# PY32F021xx register map
Vendor: Puya; Series: PY32C; File version: 1.0.0
Arm 32-bit Cortex-M0+ Microcontroller based device, CPU clock up to 48 MHz.
CPU: CM0+ r0p1, little endian, no MPU, no FPU, 4 interrupt priority bits
Registers are 32-bit, read-write, reset 0x0 unless marked. A register's access mark holds for its fields unless they carry their own. Offsets are from the block's base; lines under a group give offsets from that group; [hi:lo] are bit positions; {n}, {i} and the like mark numbered series; 'fields as' and 'values as' point back to an identical list; <NAME> marks a mode.

## Memory map
0x40000000 TIM2 size 0x400 — General purpose timer
0x40002000 TIM14 size 0x400 — General purpose timer
0x40002800 RTC size 0x400 — Real time clock
0x40002C00 WWDG size 0x400 — Window watchdog
0x40003000 IWDG size 0x400 — Independent watchdog
0x40003800 SPI2 size 0x400
0x40004400 USART2 size 0x400
0x40005400 I2C1 size 0x400 — Inter integrated circuit
0x40007000 PWR size 0x400 — Power control
0x40007C00 LPTIM size 0x400 — Low power timer
0x40010000 SYSCFG size 0x30 — System configuration controller
0x40010200 COMP1 size 0x10 — Comparator
0x40010210 COMP2 size 0x10 — Comparator
0x40010300 OPA size 0x400 — Operational amplifier
0x40012400 ADC size 0x400 — Analog to Digital Converter
0x40012C00 TIM1 size 0x400 — Advanced timer
0x40013000 SPI1 size 0x400 — Serial peripheral interface
0x40013800 USART1 size 0x400 — Universal synchronous asynchronous receivertransmitter
0x40014400 TIM16 size 0x400 — General purpose timer
0x40014800 TIM17 size 0x400
0x40015800 DBGMCU size 0x400 — Debug support
0x40020000 DMA size 0x400 — Direct memory access
0x40021000 RCC size 0x400 — Reset and clock control
0x40021800 EXTI size 0x400 — External interrupt/eventcontroller
0x40022000 FLASH size 0x400
0x40023000 CRC size 0x400 — CRC calculation unit
0x40023400 CORDIC size 0x400 — Digital Co-process Operation
0x40023800 DIV size 0x400 — Divider
0x50000000 GPIOA size 0x400 — General-purpose I/Os
0x50000400 GPIOB size 0x400
0x50001400 GPIOF size 0x400

## Interrupts
0 WWDG — Window WatchDog Interrupt
1 PVD (EXTI) — PVD Interrupt through EXTI Lines 16
2 RTC — RTC Interrupt through EXTI Lines 19
3 FLASH — FLASH global Interrupt
4 RCC — RCC global Interrupt
5 EXTI0_1 (EXTI) — EXTI Line 0 and 1 Interrupt
6 EXTI2_3 (EXTI) — EXTI Line 2 and 3 Interrupt
7 EXTI4_15 (EXTI) — EXTI Line 4 to 15 Interrupt
9 DMA_Channel1 (DMA) — DMA Channel 1 Interrupt
10 DMA_Channel2_3 (DMA) — DMA Channel 2 and Channel 3 Interrupt
12 ADC_COMP (ADC) — ADC and COMP Interrupt through EXTI Lines 17 and 18
13 TIM1_BRK_UP_TRG_COM (TIM1) — TIM1 Break, Update, Trigger and Commutation Interrupt
14 TIM1_CC (TIM1) — TIM1 Capture Compare Interrupt
15 TIM2 — TIM2 global Interrupt
17 LPTIM — LPTIM global Interrupt
19 TIM14 — TIM14 global Interrupt
21 TIM16 — TIM16 global Interrupt
22 TIM17 — TIM17 global Interrupt
23 I2C1 — I2C1 global Interrupt
25 SPI1 — SPI1 global Interrupt
26 SPI2 — SPI2 global Interrupt
27 USART1 — USART1 global Interrupt
28 USART2 — USART2 global Interrupt
30 SQRT (CORDIC) — SQRT global Interrupt
31 CORDIC — CORDIC global Interrupt

## COMP1 — Comparator
Base 0x40010200
Same registers: COMP2 0x40010210
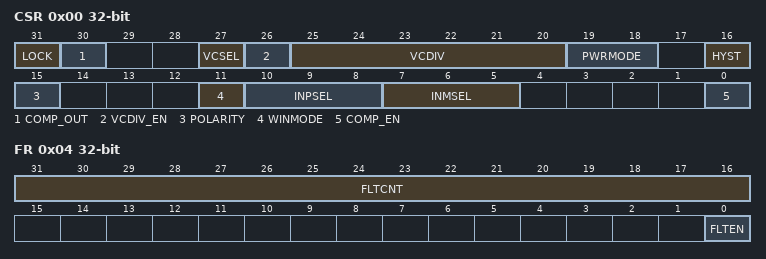
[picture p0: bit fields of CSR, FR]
0x00 CSR — COMP control and status register
  [31] LOCK — CSR register lock
  [30] COMP_OUT — Comparator output status
  [27] VCSEL — Comparator vcsel
  [26] VCDIV_EN — Comparator vcdiv enable
  [25:20] VCDIV — Comparator vcdiv
  [19:18] PWRMODE — Comparator power mode selector
  [16] HYST — Comparator hysteresis enable selector
  [15] POLARITY — Comparator polarity selector
  [11] WINMODE — Comparator non-inverting input selector for window mode
  [10:8] INPSEL — Comparator signal selector for non-inverting input
  [7:5] INMSEL — Comparator signal selector for inverting input INM
  [0] COMP_EN — COMP enable bit
0x04 FR — Comparator Filterregister
  [31:16] FLTCNT — Comparator filter and counter
  [0] FLTEN — Filter enable bit

## CORDIC — Digital Co-process Operation
Base 0x40023400
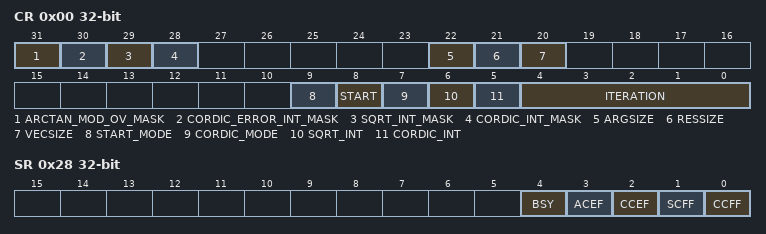
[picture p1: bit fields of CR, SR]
0x00 CR — CORDIC control register
  [31] ARCTAN_MOD_OV_MASK, [30] CORDIC_ERROR_INT_MASK, [29] SQRT_INT_MASK, [28] CORDIC_INT_MASK, [22] ARGSIZE, [21] RESSIZE, [20] VECSIZE, [9] START_MODE, [8] START, [7] CORDIC_MODE, [6] SQRT_INT, [5] CORDIC_INT, [4:0] ITERATION
0x04 THETA — SIN or COS input theta register
0x08 SIN ro — CORDIC SIN result register
  [23:0] SIN — SIN result
0x0C COS ro — CORDIC COS result register
  [23:0] COS — COS result
0x10 X — Arctan input coordinate register
  [23:0] X — arctan or module X register
0x14 Y — Arctan input coordinate register
  [23:0] Y — arctan or module Y register
0x18 MOD ro — CORDIC Mod result register
  [24:0] MOD — mod result
0x1C ARCTAN ro — CORDIC ARCTAN result register
  [15:0] ARCTAN — arctan result
0x20 DSP_RAD — CORDIC Radicand register
  [31:0] RAD — Number of open parties
0x24 DSP_SQRT ro — CORDIC SQRT result register
  [15:0] SQRT — sqrt result
0x28 SR ro — CORDIC Status register
  [4] BSY
  [3] ACEF — desc ACFF
  [2] CCEF — desc CCFF
  [1] SCFF
  [0] CCFF
